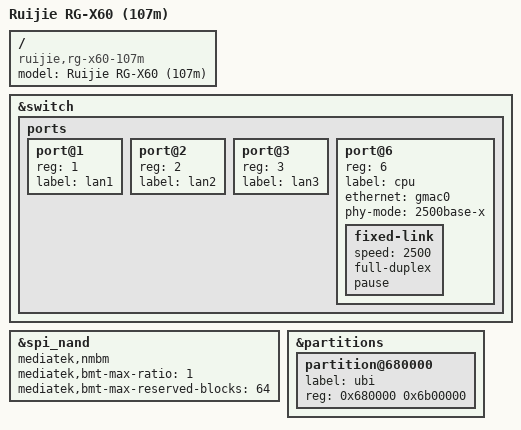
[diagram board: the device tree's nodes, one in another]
// SPDX-License-Identifier: GPL-2.0-or-later OR MIT

/dts-v1/;
#include "mt7986a-ruijie-rg-x60-base.dtsi"

&switch {
	ports {
		#address-cells = <1>;
		#size-cells = <0>;

		port@1 {
			reg = <1>;
			label = "lan1";
		};

		port@2 {
			reg = <2>;
			label = "lan2";
		};

		port@3 {
			reg = <3>;
			label = "lan3";
		};

		port@6 {
			reg = <6>;
			label = "cpu";
			ethernet = <&gmac0>;
			phy-mode = "2500base-x";

			fixed-link {
				speed = <2500>;
				full-duplex;
				pause;
			};
		};
	};
};

&spi_nand {
	mediatek,nmbm;
	mediatek,bmt-max-ratio = <1>;
	mediatek,bmt-max-reserved-blocks = <64>;
};

&partitions {
	partition@680000 {
		label = "ubi";
		reg = <0x680000 0x6b00000>;
	};
};

/ {
	compatible = "ruijie,rg-x60-107m", "mediatek,mt7986a";
	model = "Ruijie RG-X60 (107m)";
};
